# RSS_RCM register map
Vendor: Texas Instruments
Peripheral module from a debugger description file (folder awr29xx).
Registers are 32-bit, read-write, no defined reset value unless marked. A register's access mark holds for its fields unless they carry their own. Offsets are as the file gives them; lines under a group give offsets from that group; [hi:lo] are bit positions; {n}, {i} and the like mark numbered series; 'fields as' and 'values as' point back to an identical list; <NAME> marks a mode.

## RSS_RCM
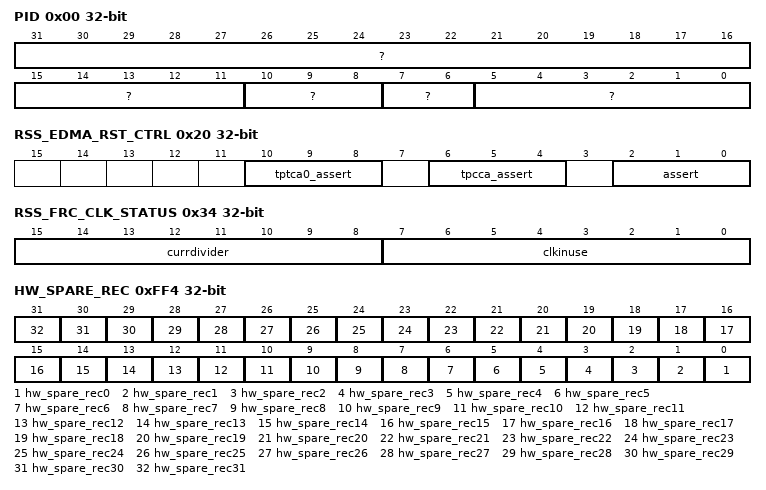
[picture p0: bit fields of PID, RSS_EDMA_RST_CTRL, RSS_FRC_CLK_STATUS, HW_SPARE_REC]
0x00 PID ro
  [31:16] ?, [15:11] ?, [10:8] ?, [7:6] ?, [5:0] ?
0x04 HW_REG0
  [31:0] hwreg — HW Reserved regiser
0x08 HW_REG1
  [31:0] hwreg — HW Reserved regiser
0x0C PREVIOUS_NAME
  [31:0] hwreg — HW Reserved regiser
0x10 HW_REG3
  [31:0] hwreg — HW Reserved regiser
0x14 RSS_CSI2A_SYS_CLK_GATE
  [2:0] gated — Clock gatring config for RSS CSI2A Data should be loaded as multibit. Write 3'b000 : Clock is ungated Write 3'b111 : Clock is gated
0x18 RSS_BSS_SYS_CLK_GATE
  [2:0] gated — Clock gatring config for RSS BSS Data should be loaded as multibit. Write 3'b000 : Clock is ungated Write 3'b111 : Clock is gated
0x1C RSS_CSI2A_RST_CTRL
  [2:0] assert — This feature is for debug pupose only. software need to ensure the correct state of Device/IP before configuring this reset control for RSS CSI2A Data should be loaded as multibit. Write 3'b000: Reset is not asserted by SW. There could be another reset source which could reset the module. Refer to RCM spec for more details Write 3'b111 : Reset is asserted by SW
0x20 RSS_EDMA_RST_CTRL
  [10:8] tptca0_assert — writing '111' will reset MSS_TPCCA
  [6:4] tpcca_assert — This feature is for debug pupose only. software need to ensure the correct state of Device/IP before configuring this reset control for RSS EDMA Data should be loaded as multibit. Write 3'b000: Reset is not asserted by SW. There could be another reset source which could reset the module. Refer to RCM spec for more details Write 3'b111 : Reset is asserted by SW
  [2:0] assert — This feature is for debug pupose only. software need to ensure the correct state of Device/IP before configuring this reset control for RSS EDMA Data should be loaded as multibit. Write 3'b000: Reset is not asserted by SW. There could be another reset source which could reset the module. Refer to RCM spec for more details Write 3'b111 : Reset is asserted by SW
0x24 RSS_BSS_RST_CTRL
  [2:0] assert — This feature is for debug pupose only. software need to ensure the correct state of Device/IP before configuring this reset control for RSS BSS Data should be loaded as multibit. Write 3'b000: Reset is not asserted by SW. There could be another reset source which could reset the module. Refer to RCM spec for more details Write 3'b111 : Reset is asserted by SW
0x28 RSS_FRC_CLK_SRC_SEL
  [11:0] clksrcsel — Select line for selecting source clock for FRC.Data should be loaded as multibit. For example: if '0x5' should be selected then '0x555' should be configured to the register. Refer to TPR12 clock spec for source clock reference
0x2C RSS_FRC_CLK_GATE
  [2:0] gated — writing 3'b111 will gate the clock for FRC
0x30 RSS_FRC_CLK_DIV_VAL
  [11:0] clkdivr — Divider value for FRC selected clock.Data should be loaded as multibit. For example: if divider value of 8(1000) should be selected then '100010001000' should be configured to the register. Refer to TPR12 clock planner for clock reference
0x34 RSS_FRC_CLK_STATUS ro
  [15:8] currdivider — Status shows the current divider value choosen for FRC
  [7:0] clkinuse — Status shows the source clock slected for FRC
0x38 RSS_FRC_RST_CTRL
  [2:0] assert — This feature is for debug pupose only. software need to ensure the correct state of Device/IP before configuring this reset control for RSS FRC Data should be loaded as multibit. Write 3'b000: Reset is not asserted by SW. There could be another reset source which could reset the module. Refer to RCM spec for more details Write 3'b111 : Reset is asserted by SW
{0xFD0+4i} HW_SPARE_RW{i} (i=0..3)
  [31:0] hw_spare_rw{i} — Reserved for HW R&D
{0xFE0+4i} HW_SPARE_RO{i} ro (i=0..3)
  [31:0] hw_spare_ro{i} — Reserved for HW R&D
0xFF0 HW_SPARE_WPH
  [31:0] hw_spare_wph — Reserved for HW R&D
0xFF4 HW_SPARE_REC
  [n] hw_spare_rec{n} (n=0..31) — Reserved for HW R&D
0x1008 LOCK0_KICK0 — - KICK0 component
  [31:0] ?
0x100C LOCK0_KICK1 — - KICK1 component
  [31:0] ?
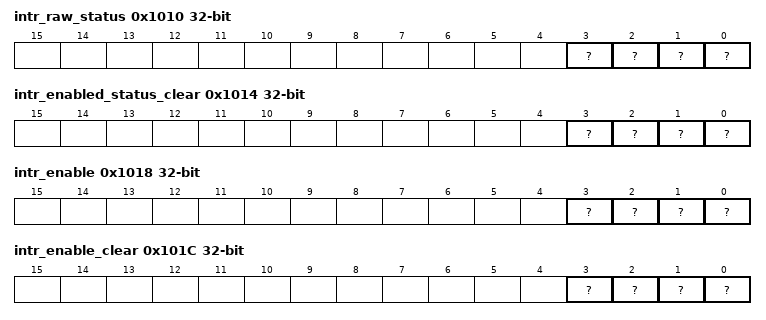
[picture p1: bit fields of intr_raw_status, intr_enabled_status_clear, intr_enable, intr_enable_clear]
0x1010 intr_raw_status — Interrupt Raw Status/Set Register
  [3] ? — Proxy0 access violation error. Raw status is read. Write a 1 to set the status. Writing a 0 has no effect.
  [2] ? — Kick access violation error. Raw status is read. Write a 1 to set the status. Writing a 0 has no effect.
  [1] ? — Addressing violation error. Raw status is read. Write a 1 to set the status. Writing a 0 has no effect.
  [0] ? — Protection violation error. Raw status is read. Write a 1 to set the status. Writing a 0 has no effect.
0x1014 intr_enabled_status_clear — Interrupt Enabled Status/Clear register
  [3] ? — Proxy0 access violation error. Enabled status is read. Write a 1 to clear the status. Writing a 0 has no effect.
  [2] ? — Kick access violation error. Enabled status is read. Write a 1 to clear the status. Writing a 0 has no effect.
  [1] ? — Addressing violation error. Enabled status is read. Write a 1 to clear the status. Writing a 0 has no effect.
  [0] ? — Protection violation error. Enabled status is read. Write a 1 to clear the status. Writing a 0 has no effect.
0x1018 intr_enable — Interrupt Enable register
  [3] ? — Proxy0 access violation error enable. Write a 1 to set the enable. Writing a 0 has no effect.
  [2] ? — Kick access violation error enable. Write a 1 to set the enable. Writing a 0 has no effect.
  [1] ? — Addressing violation error enable. Write a 1 to set the enable. Writing a 0 has no effect.
  [0] ? — Protection violation error enable. Write a 1 to set the enable. Writing a 0 has no effect.
0x101C intr_enable_clear — Interrupt Enable Clear register
  [3] ? — Proxy0 access violation error enable clear. Write a 1 to clear the enable. Writing a 0 has no effect.
  [2] ? — Kick access violation error enable clear. Write a 1 to clear the enable. Writing a 0 has no effect.
  [1] ? — Addressing violation error enable clear. Write a 1 to clear the enable. Writing a 0 has no effect.
  [0] ? — Protection violation error enable clear. Write a 1 to clear the enable. Writing a 0 has no effect.
0x1020 eoi
  [7:0] ? — EOI vector value. Write this with interrupt distribution value in the chip.
0x1024 fault_address ro
  [31:0] ? — Fault Address.
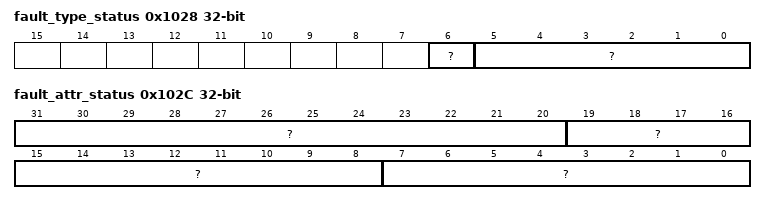
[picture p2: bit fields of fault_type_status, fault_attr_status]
0x1028 fault_type_status ro
  [6] ? — Non-secure access.
  [5:0] ? — Fault Type 10_0000 = Supervisor read fault - priv = 1 dir = 1 dtype != 1 01_0000 = Supervisor write fault - priv = 1 dir = 0 00_1000 = Supervisor execute fault - priv = 1 dir = 1 dtype = 1 00_0100 = User read fault - priv = 0 dir = 1 dtype = 1 00_0010 = User write fault - priv = 0 dir = 0 00_0001 = User execute fault - priv = 0 dir = 1 dtype = 1 00_0000 = No fault
0x102C fault_attr_status ro — Fault Attribute Status register
  [31:20] ? — XID.
  [19:8] ? — Route ID.
  [7:0] ? — Privilege ID.
0x1030 fault_clear wo
  [0] ? — Fault clear. Writing a 1 clears the current fault. Writing a 0 has no effect.
